# TC35680 register map
Vendor: Toshiba Electronic Devices and Storage Corporation; File version: 0.1
CPU: CM0 r0p0, little endian, no MPU, no FPU, 4 interrupt priority bits
Registers are 32-bit, read-write, no defined reset value unless marked. A register's access mark holds for its fields unless they carry their own. Offsets are from the block's base; [hi:lo] are bit positions; {n}, {i} and the like mark numbered series.

## GPIO — General Purpose Input/Output
Base 0x4004E000
{0x0+4i} GPIO_MON{i} ro (i=0..17) — GPIO{i} input monitor
  [0] GPIOMon — GPIO input monitor data. Monitors the input of GPIO. 1: High input. 0: Low input. Not dependent on the GppOutEn or hte GppMuxCfg.
0x100 GPIO_OUT0 — GPIO0 output data
  [0] GPIOOut — GPIO output data Set the output level of the GPIOX.. 1: High output. 0: Low output. The value is output only when GPIOOutEnX = 1 and GPIOMuxCfgX = 0.
{0x100+4i} GPIO_OUT{i} (i=1..17) — GPIO{i} output data
  [0] GPIOOut — GPIO output data Set the output level of the GPIOX. 1: High output. 0: Low output. The value is output only when GPIOOutEnX = 1 and GPIOMuxCfgX = 0.
{0x200+4i} GPIO_OUT_EN{i} (i=0..17) — GPIO{i} output enable
  [0] GPIOOutEn — GPIO output enable. Enables GPIO output. 1: output enable. 0: output disable
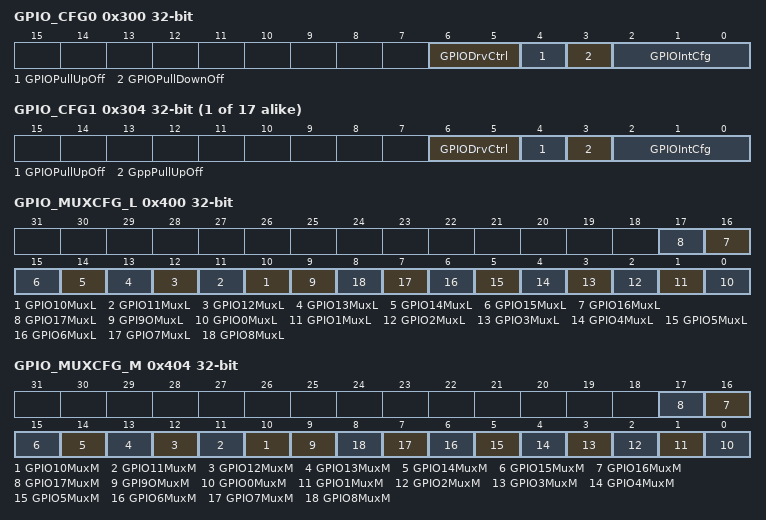
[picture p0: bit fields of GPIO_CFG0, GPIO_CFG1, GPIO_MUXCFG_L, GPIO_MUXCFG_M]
0x300 GPIO_CFG0 — GPIO0 config
  [6:5] GPIODrvCtrl — GPIO0 drive control. To set GPIO drive settings. 00: 1 mA. 01: 1.5 mA (default). 10: 2 mA. 11: 4 mA. Valid when the GPIO is set as output regardless of GPIOMuxCfg.
  [4] GPIOPullUpOff — GPIO pull-up resister off. Turn on/off the internal pull up resiter. 1: Internal pull-up off. 0: Internal pull-up on. When both GPIOPullDownOff = 0 and GPIOPullUpOff = 0 are to be set, the chip forces GPIOPullDownOff = 1 and GPIOPullUpOff = 0. Valid when the GPIO is set as input regardless of the GppMuxCfg.
  [3] GPIOPullDownOff — GPIO pull-down resister off. Turn on/off the internal pull down resiter. 1: Internal pull-down off. 0: Internal pull-down on. When both GPIOPullDownOff = 0 and GPIOPullUpOff = 0 are to be set, the chip forces GPIOPullDownOff = 1 and GPIOPullUpOff = 0. Valid when the GPIO is set as input regardless of the GppMuxCfg.
  [2:0] GPIOIntCfg — GPIO interrupt configuration (initial 00, R/W). Sets the polarity to use the GPIO as an external interrupt. 000: prohibit the interrupt. 001: detect rising edge. 010: detect falling edge. 011: detect both edges. 100: detect high level. 101: detect low level
{0x300+4i} GPIO_CFG{i} (i=1..17) — GPIO{i} config
  [6:5] GPIODrvCtrl — GPIO{i} drive control. To set GPIO drive settings. 00: 1 mA. 01: 1.5 mA (default). 10: 2 mA. 11: 4 mA. Valid when the GPIO is set as output regardless of GPIOMuxCfg.
  [4] GPIOPullUpOff — GPIO pull-up resister off. Turn on/off the internal pull up resiter. 1: Internal pull-up off. 0: Internal pull-up on. When both GPIOPullDownOff = 0 and GPIOPullUpOff = 0 are to be set, the chip forces GPIOPullDownOff = 1 and GPIOPullUpOff = 0. Valid when the GPIO is set as input regardless of the GppMuxCfg.
  [3] GppPullUpOff — GPIO pull-down resister off. Turn on/off the internal pull down resiter. 1: Internal pull-down off. 0: Internal pull-down on. When both GPIOPullDownOff = 0 and GPIOPullUpOff = 0 are to be set, the chip forces GPIOPullDownOff = 1 and GPIOPullUpOff = 0. Valid when the GPIO is set as input regardless of the GppMuxCfg.
  [2:0] GPIOIntCfg — GPIO interrupt configuration (initial 00, R/W). Sets the polarity to use the GPIO as an external interrupt. 000: prohibit the interrupt. 001: detect rising edge. 010: detect falling edge. 011: detect both edges. 100: detect high level. 101: detect low level
0x400 GPIO_MUXCFG_L — GPIO multiplexer config L
  [n] GPIO{n}MuxL (n=10..17) — Bit 0 of GPIO multiplexer configuration.
  [9] GPI9OMuxL — Bit 0 of GPIO multiplexer configuration.
  [n] GPIO{n}MuxL (n=0..8) — Bit 0 of GPIO multiplexer configuration.
0x404 GPIO_MUXCFG_M — GPIO multiplexer config M
  [n] GPIO{n}MuxM (n=10..17) — Bit 1 of GPIO multiplexer configuration.
  [9] GPI9OMuxM — Bit 1 of GPIO multiplexer configuration.
  [n] GPIO{n}MuxM (n=0..8) — Bit 1 of GPIO multiplexer configuration.
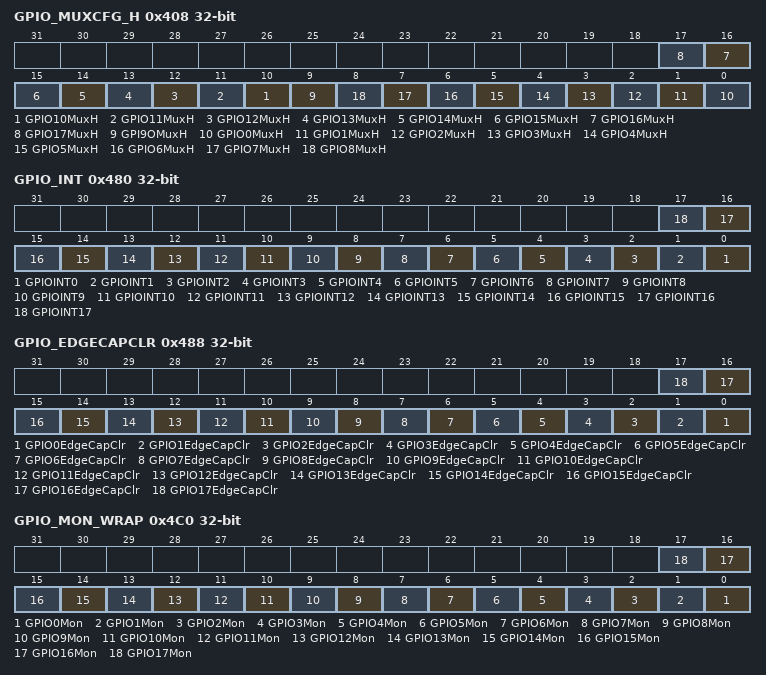
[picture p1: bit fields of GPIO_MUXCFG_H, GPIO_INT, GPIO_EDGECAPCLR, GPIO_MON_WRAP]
0x408 GPIO_MUXCFG_H — GPIO multiplexer config H
  [n] GPIO{n}MuxH (n=10..17) — Bit 2 of GPIO multiplexer configuration.
  [9] GPI9OMuxH — Bit 2 of GPIO multiplexer configuration.
  [n] GPIO{n}MuxH (n=0..8) — Bit 2 of GPIO multiplexer configuration.
0x480 GPIO_INT ro — GPIO interrupt read
  [n] GPIOINT{n} (n=0..17) — Read interrupt on the GPIO. 1: Interrupted. 0: Not interrupted
0x488 GPIO_EDGECAPCLR — GPIO edge interrupt capture clear
  [n] GPIO{n}EdgeCapClr (n=0..17) — Clear edge interrput capture on the GPIO. 1: Clear. 0: Not clear
0x490 GPIO_OBSMUXCFG — GPIO Observation function selection register
  [3:0] ObsMuxCfg — Always set 3.
0x4C0 GPIO_MON_WRAP ro — GPIO Input Monitor Wrap Register
  [n] GPIO{n}Mon (n=0..17) — GPIO{n} input monitor data. Monitors the input of GPIO{n}. 1: High input. 0: Low input
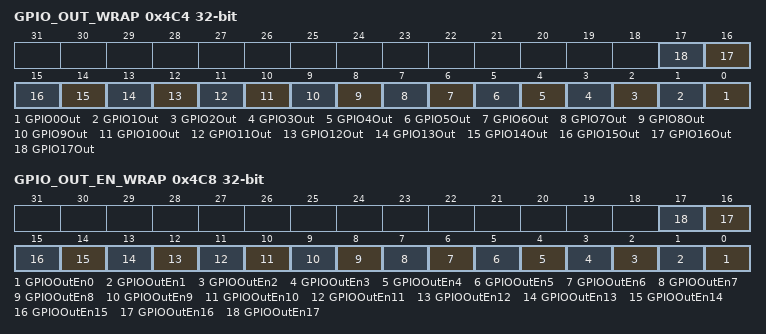
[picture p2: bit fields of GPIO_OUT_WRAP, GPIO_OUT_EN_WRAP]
0x4C4 GPIO_OUT_WRAP — GPIO Output data Wrap Register
  [n] GPIO{n}Out (n=0..17) — GPIO{n} output data. Set the output level of GPIO{n}. 1: High output. 0: Low output
0x4C8 GPIO_OUT_EN_WRAP — GPIO Output Enable Wrap Register
  [n] GPIOOutEn{n} (n=0..17) — GPIO{n} output enable. Enables GPIO{n} output. 1: Output enable. 0: Output disable
